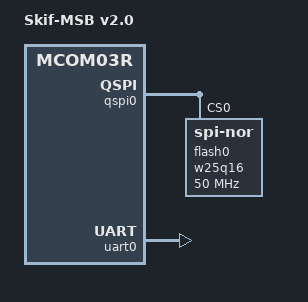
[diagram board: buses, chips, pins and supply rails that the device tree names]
// SPDX-License-Identifier: GPL-2.0+
// Copyright 2025 RnD Center "ELVEES", JSC

/dts-v1/;

#include <dt-bindings/gpio/gpio.h>

#include "mcom03r.dtsi"

/ {
	model = "Skif-MSB v2.0";
	compatible = "elvees,skifmsb-v2.0",
		     "elvees,skifmsb",
		     "elvees,mcom03r";

	chosen {
		stdout-path = "serial0:115200n8";
	};
};

&qspi0 {
	status = "okay";

	flash0: w25q16@0 {
		#address-cells = <1>;
		#size-cells = <1>;
		compatible = "jedec,spi-nor", "spi-flash";
		reg = <0x0>;

		spi-max-frequency = <50000000>;

		spi-tx-bus-width = <4>;
		spi-rx-bus-width = <4>;
	};
};

&uart0 {
	status = "okay";
	clock-frequency = <27920454>;
};
